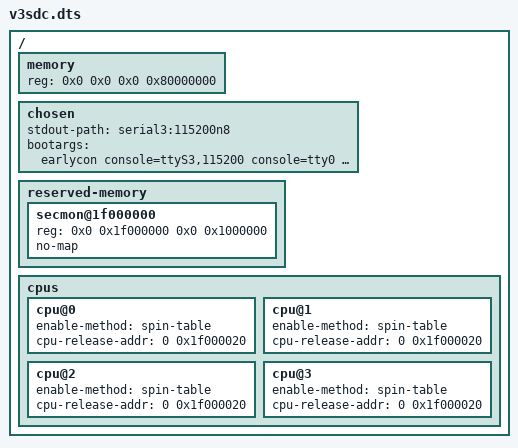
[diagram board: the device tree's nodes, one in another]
// SPDX-License-Identifier: (GPL-2.0+ OR MIT)

/dts-v1/;
#include "v3caninos.dtsi"

/ {
	memory {
		device_type = "memory";
		reg = <0x0 0x0 0x0 0x80000000>;
	};
	
	chosen {
		/* keep_bootcon console=tty0 loglevel=7*/
		stdout-path = "serial3:115200n8";
		bootargs = "earlycon console=ttyS3,115200 console=tty0 root=/dev/mmcblk0p1 rw rootwait no_console_suspend";
	};
	
	reserved-memory {
		/* reserve 16MB for secure monitor */
		secmon@1f000000 {
			reg = <0x0 0x1f000000 0x0 0x1000000>;
			no-map;
		};
	};
	
	cpus {
		cpu@0 {
			enable-method = "spin-table";
			cpu-release-addr = <0 0x1f000020>;
		};
		cpu@1 {
			enable-method = "spin-table";
			cpu-release-addr = <0 0x1f000020>;
		};
		cpu@2 {
			enable-method = "spin-table";
			cpu-release-addr = <0 0x1f000020>;
		};
		cpu@3 {
			enable-method = "spin-table";
			cpu-release-addr = <0 0x1f000020>;
		};
	};
};

